# COMPUTE_CLUSTER_ARM_COREPACK_0_COMPUTE_CLUSTER_ARM_COREPACK_0_APBADDR_CTI_CPU1_000730120000h register map
Vendor: Texas Instruments
Peripheral module from a debugger description file (folder am62L).
Registers are 32-bit, read-write, reset 0x0 unless marked. A register's access mark holds for its fields unless they carry their own. Offsets are as the file gives them; lines under a group give offsets from that group; [hi:lo] are bit positions; {n}, {i} and the like mark numbered series; 'fields as' and 'values as' point back to an identical list; <NAME> marks a mode.

## COMPUTE_CLUSTER_ARM_COREPACK_0_APBADDR_CTI_CPU1
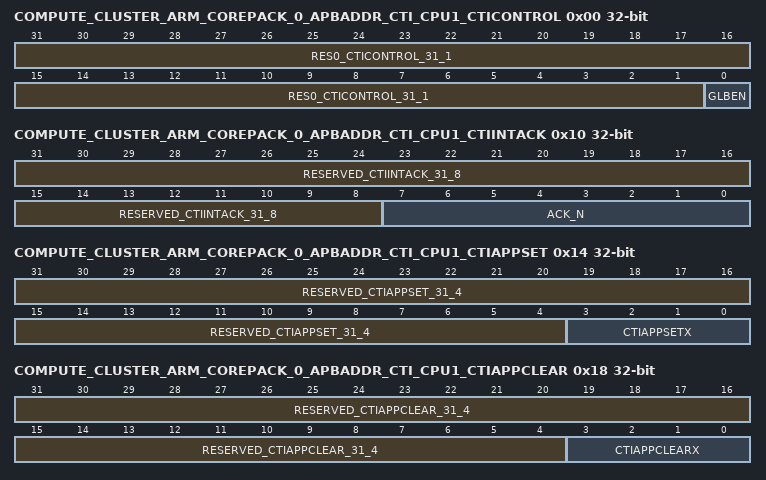
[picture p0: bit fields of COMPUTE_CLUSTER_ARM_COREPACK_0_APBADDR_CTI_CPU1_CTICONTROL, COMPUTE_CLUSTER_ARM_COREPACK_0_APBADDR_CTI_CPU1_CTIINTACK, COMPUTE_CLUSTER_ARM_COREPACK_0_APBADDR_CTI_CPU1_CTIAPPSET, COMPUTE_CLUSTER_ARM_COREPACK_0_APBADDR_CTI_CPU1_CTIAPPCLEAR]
0x00 COMPUTE_CLUSTER_ARM_COREPACK_0_APBADDR_CTI_CPU1_CTICONTROL — CTI Control Register
  [31:1] RES0_CTICONTROL_31_1 — Reserved, RES0.
  [0] GLBEN — Enables or disables the CTI mapping functions. Possible values of this field are: 0 CTI mapping functions disabled. 1 CTI mapping functions enabled. When the mapping functions are disabled, no new events are signaled on either output triggers or output channels. If a previously asserted output trigger has not been acknowledged, it remains asserted after the mapping functions are disabled. All output triggers are disabled by CTI reset.
0x10 COMPUTE_CLUSTER_ARM_COREPACK_0_APBADDR_CTI_CPU1_CTIINTACK — CTI Output Trigger Acknowledge Register
  [31:8] RESERVED_CTIINTACK_31_8 — Reserved RES0
  [7:0] ACK_N — Can be used to create soft acknowledges for output triggers
0x14 COMPUTE_CLUSTER_ARM_COREPACK_0_APBADDR_CTI_CPU1_CTIAPPSET — CTI Application Trigger Set Register
  [31:4] RESERVED_CTIAPPSET_31_4 — Reserved RES0
  [3:0] CTIAPPSETX — Application trigger <x> enable
0x18 COMPUTE_CLUSTER_ARM_COREPACK_0_APBADDR_CTI_CPU1_CTIAPPCLEAR — CTI Application Trigger Clear Register
  [31:4] RESERVED_CTIAPPCLEAR_31_4 — Reserved RES0
  [3:0] CTIAPPCLEARX — Application trigger <x> disable
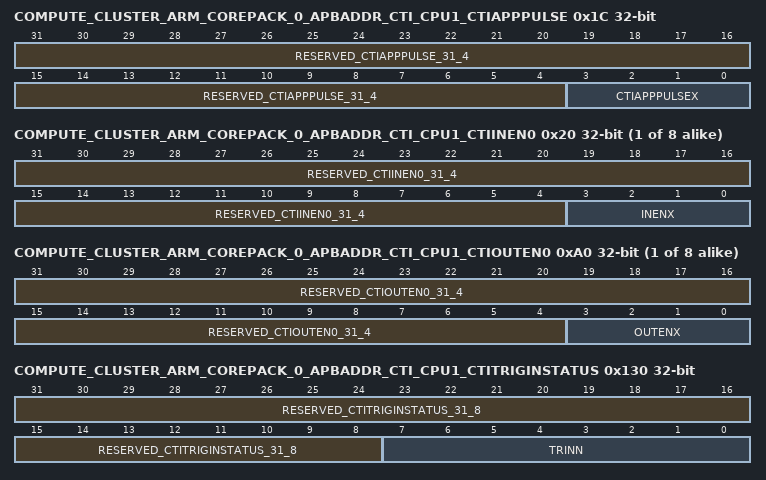
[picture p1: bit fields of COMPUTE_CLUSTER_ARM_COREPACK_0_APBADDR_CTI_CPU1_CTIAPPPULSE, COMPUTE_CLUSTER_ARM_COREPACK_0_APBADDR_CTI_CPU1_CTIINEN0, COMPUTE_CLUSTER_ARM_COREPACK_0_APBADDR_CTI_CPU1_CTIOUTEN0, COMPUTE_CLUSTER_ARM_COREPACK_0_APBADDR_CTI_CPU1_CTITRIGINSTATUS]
0x1C COMPUTE_CLUSTER_ARM_COREPACK_0_APBADDR_CTI_CPU1_CTIAPPPULSE — CTI Application Pulse Register
  [31:4] RESERVED_CTIAPPPULSE_31_4 — Reserved RES0
  [3:0] CTIAPPPULSEX — Generate event pulse on ECT channel <x>.
{0x20+4i} COMPUTE_CLUSTER_ARM_COREPACK_0_APBADDR_CTI_CPU1_CTIINEN{i} (i=0..7) — CTI Input Trigger to Output Channel Enable Register {i}
  [31:4] RESERVED_CTIINEN{i}_31_4 — Reserved RES0
  [3:0] INENX — Input trigger {i} to output channel <x> enable
{0xA0+4i} COMPUTE_CLUSTER_ARM_COREPACK_0_APBADDR_CTI_CPU1_CTIOUTEN{i} (i=0..7) — CTI Input Channel to Output Trigger Enable Register {i}
  [31:4] RESERVED_CTIOUTEN{i}_31_4 — Reserved RES0
  [3:0] OUTENX — Input channel <x> to output trigger {i} enable
0x130 COMPUTE_CLUSTER_ARM_COREPACK_0_APBADDR_CTI_CPU1_CTITRIGINSTATUS — CTI Trigger In Status Register
  [31:8] RESERVED_CTITRIGINSTATUS_31_8 — Reserved RES0
  [7:0] TRINN — Provides the status of the trigger inputs
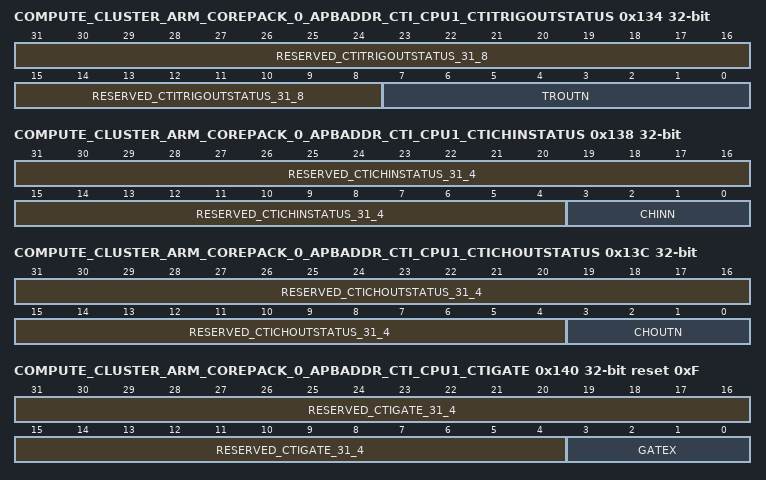
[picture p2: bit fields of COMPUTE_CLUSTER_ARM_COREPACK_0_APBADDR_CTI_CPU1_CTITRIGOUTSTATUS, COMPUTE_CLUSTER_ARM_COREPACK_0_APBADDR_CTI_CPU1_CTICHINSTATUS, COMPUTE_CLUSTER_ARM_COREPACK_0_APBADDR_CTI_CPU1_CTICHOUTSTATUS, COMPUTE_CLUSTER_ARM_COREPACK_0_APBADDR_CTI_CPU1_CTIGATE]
0x134 COMPUTE_CLUSTER_ARM_COREPACK_0_APBADDR_CTI_CPU1_CTITRIGOUTSTATUS — CTI Trigger Out Status Register
  [31:8] RESERVED_CTITRIGOUTSTATUS_31_8 — Reserved RES0
  [7:0] TROUTN — Provides the status of the trigger outputs
0x138 COMPUTE_CLUSTER_ARM_COREPACK_0_APBADDR_CTI_CPU1_CTICHINSTATUS — CTI Channel In Status Register
  [31:4] RESERVED_CTICHINSTATUS_31_4 — Reserved RES0
  [3:0] CHINN — Provides the raw status of the ECT channel inputs to the CTI
0x13C COMPUTE_CLUSTER_ARM_COREPACK_0_APBADDR_CTI_CPU1_CTICHOUTSTATUS — CTI Channel Out Status Register
  [31:4] RESERVED_CTICHOUTSTATUS_31_4 — Reserved RES0
  [3:0] CHOUTN — Provides the status of the ECT channel outputs from the CTI
0x140 COMPUTE_CLUSTER_ARM_COREPACK_0_APBADDR_CTI_CPU1_CTIGATE reset 0xF — CTI Channel Gate Enable Register
  [31:4] RESERVED_CTIGATE_31_4 — Reserved RES0
  [3:0] GATEX — Determines whether events on channels propagate through the CTM to other ECT components or from the CTM into the CTI
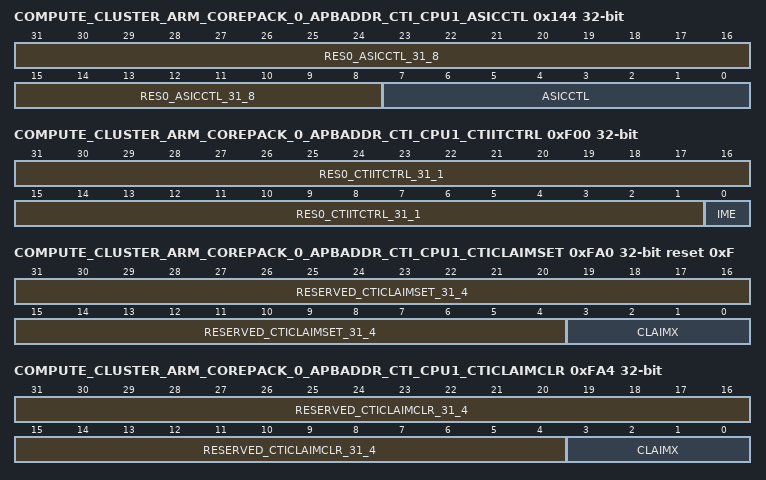
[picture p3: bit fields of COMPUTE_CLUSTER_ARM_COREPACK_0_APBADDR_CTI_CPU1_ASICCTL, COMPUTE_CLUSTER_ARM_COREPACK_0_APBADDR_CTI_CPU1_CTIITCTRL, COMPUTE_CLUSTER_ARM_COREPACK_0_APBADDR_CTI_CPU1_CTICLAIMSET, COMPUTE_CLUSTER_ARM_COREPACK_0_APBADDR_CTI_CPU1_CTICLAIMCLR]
0x144 COMPUTE_CLUSTER_ARM_COREPACK_0_APBADDR_CTI_CPU1_ASICCTL — CTI External Multiplexor Control register
  [31:8] RES0_ASICCTL_31_8 — Reserved, RES0.
  [7:0] ASICCTL — IMPLEMENTATION DEFINED ASIC control. Provides a control for external multiplexing of additional triggers into the CTI.If external multiplexing of trigger signals is implemented then the number of multiplexed signals on each trigger must be reflected in CTIDEVID.EXTMUXNUM.If CTIDEVID.EXTMUXNUM is zero, this field is RAZ.
0xF00 COMPUTE_CLUSTER_ARM_COREPACK_0_APBADDR_CTI_CPU1_CTIITCTRL — CTI Integration mode Control Register
  [31:1] RES0_CTIITCTRL_31_1 — Reserved, RES0.
  [0] IME — Integration mode enable. When IME == 1, the device reverts to an integration mode to enable integration testing or topology detection. The integration mode behavior is IMPLEMENTATION DEFINED. 0 Normal operation. 1 Integration mode enabled.
0xFA0 COMPUTE_CLUSTER_ARM_COREPACK_0_APBADDR_CTI_CPU1_CTICLAIMSET reset 0xF — CTI Claim Set
  [31:4] RESERVED_CTICLAIMSET_31_4 — Reserved RES0
  [3:0] CLAIMX — CLAIM tag set bit
0xFA4 COMPUTE_CLUSTER_ARM_COREPACK_0_APBADDR_CTI_CPU1_CTICLAIMCLR — CTI Claim Clear
  [31:4] RESERVED_CTICLAIMCLR_31_4 — Reserved RES0
  [3:0] CLAIMX — Clear CLAIM tag
0xFA8 COMPUTE_CLUSTER_ARM_COREPACK_0_APBADDR_CTI_CPU1_CTIDEVAFF0 reset 0x80000001 — CTI Device Affinity Register 0
  [31:0] CTIDEVAFF0 — MPIDR_EL1 low half. Read-only copy of the low half of MPIDR_EL1, as seen from the highest implemented exception level.
0xFAC COMPUTE_CLUSTER_ARM_COREPACK_0_APBADDR_CTI_CPU1_CTIDEVAFF1 — CTI Device Affinity Register 1
  [31:0] CTIDEVAFF1 — MPIDR_EL1 high half. Read-only copy of the high half of MPIDR_EL1, as seen from the highest implemented exception level.
0xFB0 COMPUTE_CLUSTER_ARM_COREPACK_0_APBADDR_CTI_CPU1_CTILAR — CTI Lock Access Register
  [31:0] KEY — Lock Access control. Writing the key value 0xC5ACCE55 to this field unlocks the lock, enabling write accesses to this component's registers through a memory-mapped interface.Writing any other value to this register locks the lock, disabling write accesses to this component's registers through a memory mapped interface.
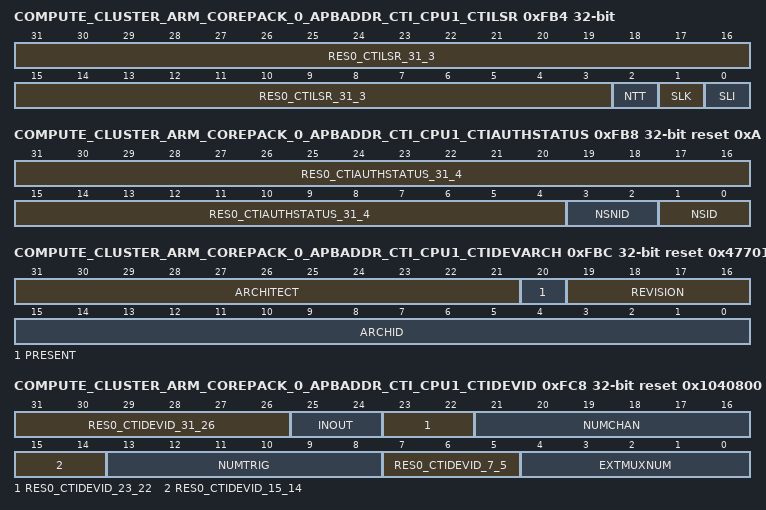
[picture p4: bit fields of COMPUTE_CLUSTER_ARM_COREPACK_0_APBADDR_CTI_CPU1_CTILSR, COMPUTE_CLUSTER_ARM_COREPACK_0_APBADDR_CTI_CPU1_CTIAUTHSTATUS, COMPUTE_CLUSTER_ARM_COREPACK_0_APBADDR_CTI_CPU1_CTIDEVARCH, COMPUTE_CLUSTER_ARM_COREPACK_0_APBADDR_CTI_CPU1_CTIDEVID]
0xFB4 COMPUTE_CLUSTER_ARM_COREPACK_0_APBADDR_CTI_CPU1_CTILSR — CTI Lock Status Register
  [31:3] RES0_CTILSR_31_3 — Reserved, RES0.
  [2] NTT — Not thirty-two bit access required. RAZ.
  [1] SLK — Software lock status for this component. For an access to LSR that is not a memory-mapped access, or when the software lock is not implemented, this field is RES0.For memory-mapped accesses when the software lock is implemented, possible values of this field are: 0 Lock clear. Writes are permitted to this component's registers. 1 Lock set. Writes to this component's registers are ignored, and reads have no side effects.
  [0] SLI — Software lock implemented. For an access to LSR that is not a memory-mapped access, this field is RAZ. For memory-mapped accesses, the value of this field is IMPLEMENTATION DEFINED. Permitted values are: 0 Software lock not implemented or not memory-mapped access. 1 Software lock implemented and memory-mapped access.
0xFB8 COMPUTE_CLUSTER_ARM_COREPACK_0_APBADDR_CTI_CPU1_CTIAUTHSTATUS reset 0xA — CTI Authentication Status Register
  [31:4] RES0_CTIAUTHSTATUS_31_4 — Reserved, RES0.
  [3:2] NSNID — If EL3 is not implemented and the processor is Secure, holds the same value as DBGAUTHSTATUS_EL1.SNID.Otherwise, holds the same value as DBGAUTHSTATUS_EL1.NSNID.
  [1:0] NSID — If EL3 is not implemented and the processor is Secure, holds the same value as DBGAUTHSTATUS_EL1.SID.Otherwise, holds the same value as DBGAUTHSTATUS_EL1.NSID.
0xFBC COMPUTE_CLUSTER_ARM_COREPACK_0_APBADDR_CTI_CPU1_CTIDEVARCH reset 0x47701A14 — CTI Device Architecture Register
  [31:21] ARCHITECT — Defines the architecture of the component. For CTI, this is ARM Limited.Bits [31:28] are the JEP 106 continuation code, 0x4.Bits [27:21] are the JEP 106 ID code, 0x3B.
  [20] PRESENT — When set to 1, indicates that the DEVARCH is present.This field is 1 in v8-A.
  [19:16] REVISION — Defines the architecture revision. For architectures defined by ARM this is the minor revision.For CTI, the revision defined by v8-A is 0x0.All other values are reserved.
  [15:0] ARCHID — Defines this part to be a v8-A debug component. For architectures defined by ARM this is further subdivided.For CTI:Bits [15:12] are the architecture version, 0x1.Bits [11:0] are the architecture part number, 0xA14.This corresponds to CTI architecture version CTIv2.
0xFC0 COMPUTE_CLUSTER_ARM_COREPACK_0_APBADDR_CTI_CPU1_CTIDEVID2 — CTI Device ID Register 2
  [31:0] RES0_CTIDEVID2_31_0 — Reserved, RES0.
0xFC4 COMPUTE_CLUSTER_ARM_COREPACK_0_APBADDR_CTI_CPU1_CTIDEVID1 — CTI Device ID Register 1
  [31:0] RES0_CTIDEVID1_31_0 — Reserved, RES0.
0xFC8 COMPUTE_CLUSTER_ARM_COREPACK_0_APBADDR_CTI_CPU1_CTIDEVID reset 0x1040800 — CTI Device ID Register 0
  [31:26] RES0_CTIDEVID_31_26 — Reserved, RES0.
  [25:24] INOUT — Input/output options. Indicates presence of the input gate. If the CTM is not implemented, this field is RAZ. 00 CTIGATE does not mask propagation of input events from external channels. 01 CTIGATE masks propagation of input events from external channels. All other values are reserved.
  [23:22] RES0_CTIDEVID_23_22 — Reserved, RES0.
  [21:16] NUMCHAN — Number of ECT channels implemented. IMPLEMENTATION DEFINED. For v8-A, valid values are: 000011 3 channels [0..2] implemented. 000100 4 channels [0..3] implemented. 000101 5 channels [0..4] implemented. 000110 6 channels [0..5] implemented. and so on up to 0b100000, 32 channels [0..31] implemented.All other values are reserved.
  [15:14] RES0_CTIDEVID_15_14 — Reserved, RES0.
  [13:8] NUMTRIG — Number of triggers implemented. IMPLEMENTATION DEFINED. This is one more than the index of the largest trigger, rather than the actual number of triggers.For v8-A, valid values are: 000011 Up to 3 triggers [0..2] implemented. 001000 Up to 8 triggers [0..7] implemented. 001001 Up to 9 triggers [0..8] implemented. 001010 Up to 10 triggers [0..9] implemented. and so on up to 0b100000, 32 triggers [0..31] implemented.All other values are reserved. If the Trace Extension is implemented, this field must be at least 001000. There is no guarantee that any of the implemented triggers, including the highest numbered, are connected to any components.
  [7:5] RES0_CTIDEVID_7_5 — Reserved, RES0.
  [4:0] EXTMUXNUM — Maximum number of external triggers available for multiplexing into the CTI. This relates only to additional external triggers outside those defined for v8-A.
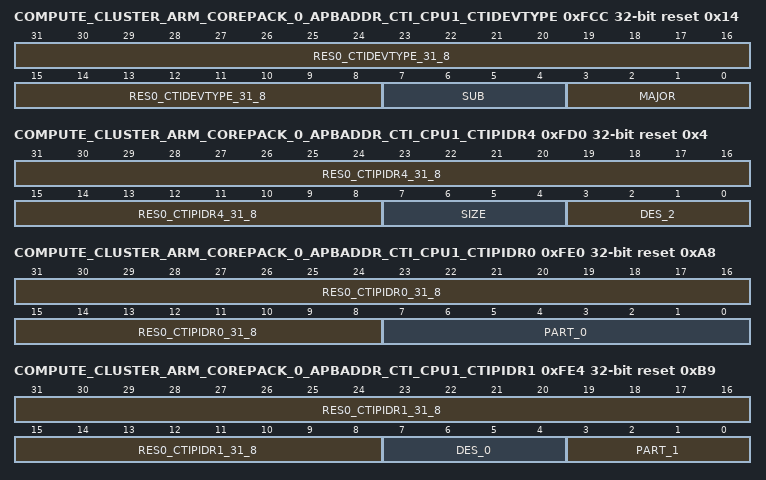
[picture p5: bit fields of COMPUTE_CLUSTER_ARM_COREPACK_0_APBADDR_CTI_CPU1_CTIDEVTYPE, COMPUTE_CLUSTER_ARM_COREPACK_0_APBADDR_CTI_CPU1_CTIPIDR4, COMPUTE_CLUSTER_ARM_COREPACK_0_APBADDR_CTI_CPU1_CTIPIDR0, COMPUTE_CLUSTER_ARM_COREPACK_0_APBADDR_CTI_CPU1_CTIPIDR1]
0xFCC COMPUTE_CLUSTER_ARM_COREPACK_0_APBADDR_CTI_CPU1_CTIDEVTYPE reset 0x14 — CTI Device Type Register
  [31:8] RES0_CTIDEVTYPE_31_8 — Reserved, RES0.
  [7:4] SUB — Subtype. Must read as 0x1 to indicate this is a processor component.
  [3:0] MAJOR — Major type. Must read as 0x4 to indicate this is a cross-trigger component.
0xFD0 COMPUTE_CLUSTER_ARM_COREPACK_0_APBADDR_CTI_CPU1_CTIPIDR4 reset 0x4 — CTI Peripheral Identification Register 4
  [31:8] RES0_CTIPIDR4_31_8 — Reserved, RES0.
  [7:4] SIZE — Size of the component. RAZ. Log2 of the number of 4KB pages from the start of the component to the end of the component ID registers.
  [3:0] DES_2 — Designer, JEP106 continuation code, least significant nibble. For ARM Limited, this field is 0b0100.
{0xFC0+4i} COMPUTE_CLUSTER_ARM_COREPACK_0_APBADDR_CTI_CPU1_CTIPIDR{i} (i=5..7) — CTI Peripheral Identification Register {i}
  [31:0] RESERVED_CTIPIDR{i}_31_0 — Reserved RES0
0xFE0 COMPUTE_CLUSTER_ARM_COREPACK_0_APBADDR_CTI_CPU1_CTIPIDR0 reset 0xA8 — CTI Peripheral Identification Register 0
  [31:8] RES0_CTIPIDR0_31_8 — Reserved, RES0.
  [7:0] PART_0 — Part number, least significant byte.
0xFE4 COMPUTE_CLUSTER_ARM_COREPACK_0_APBADDR_CTI_CPU1_CTIPIDR1 reset 0xB9 — CTI Peripheral Identification Register 1
  [31:8] RES0_CTIPIDR1_31_8 — Reserved, RES0.
  [7:4] DES_0 — Designer, least significant nibble of JEP106 ID code. For ARM Limited, this field is 0b1011.
  [3:0] PART_1 — Part number, most significant nibble.
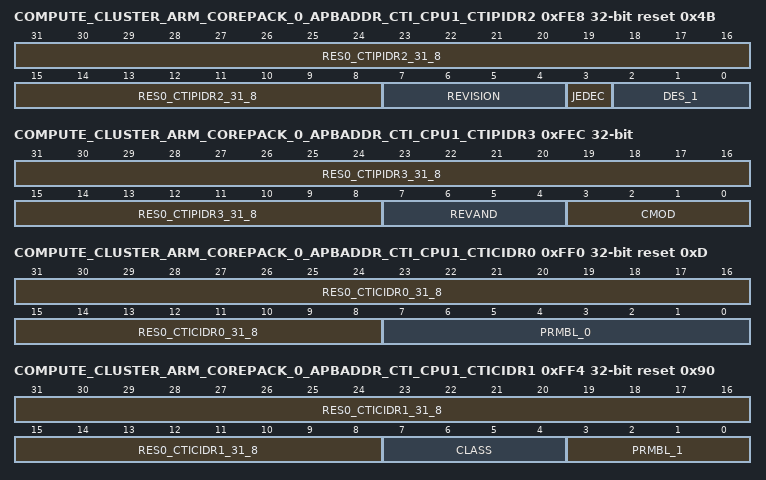
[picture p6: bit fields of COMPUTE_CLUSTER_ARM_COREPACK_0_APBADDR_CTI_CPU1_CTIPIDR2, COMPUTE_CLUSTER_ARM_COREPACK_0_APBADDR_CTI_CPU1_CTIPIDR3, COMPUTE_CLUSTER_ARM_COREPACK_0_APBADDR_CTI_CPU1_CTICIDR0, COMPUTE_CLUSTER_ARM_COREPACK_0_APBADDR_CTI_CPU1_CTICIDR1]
0xFE8 COMPUTE_CLUSTER_ARM_COREPACK_0_APBADDR_CTI_CPU1_CTIPIDR2 reset 0x4B — CTI Peripheral Identification Register 2
  [31:8] RES0_CTIPIDR2_31_8 — Reserved, RES0.
  [7:4] REVISION — Part major revision. Parts can also use this field to extend Part number to 16-bits.
  [3] JEDEC — RAO. Indicates a JEP106 identity code is used.
  [2:0] DES_1 — Designer, most significant bits of JEP106 ID code. For ARM Limited, this field is 0b011.
0xFEC COMPUTE_CLUSTER_ARM_COREPACK_0_APBADDR_CTI_CPU1_CTIPIDR3 — CTI Peripheral Identification Register 3
  [31:8] RES0_CTIPIDR3_31_8 — Reserved, RES0.
  [7:4] REVAND — Part minor revision. Parts using CTIPIDR2.REVISION as an extension to the Part number must use this field as a major revision number.
  [3:0] CMOD — Customer modified. Indicates someone other than the Designer has modified the component.
0xFF0 COMPUTE_CLUSTER_ARM_COREPACK_0_APBADDR_CTI_CPU1_CTICIDR0 reset 0xD — CTI Component Identification Register 0
  [31:8] RES0_CTICIDR0_31_8 — Reserved, RES0.
  [7:0] PRMBL_0 — Preamble. Must read as 0x0D.
0xFF4 COMPUTE_CLUSTER_ARM_COREPACK_0_APBADDR_CTI_CPU1_CTICIDR1 reset 0x90 — CTI Component Identification Register 1
  [31:8] RES0_CTICIDR1_31_8 — Reserved, RES0.
  [7:4] CLASS — Component class. Reads as 0x9, debug component.
  [3:0] PRMBL_1 — Preamble. RAZ.
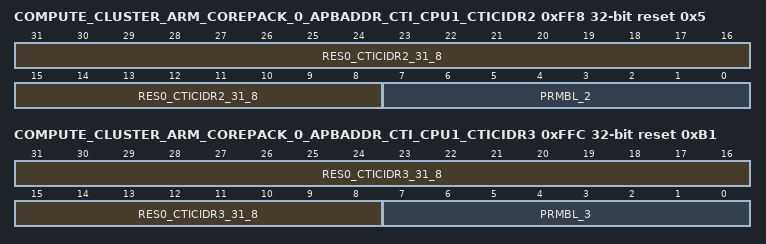
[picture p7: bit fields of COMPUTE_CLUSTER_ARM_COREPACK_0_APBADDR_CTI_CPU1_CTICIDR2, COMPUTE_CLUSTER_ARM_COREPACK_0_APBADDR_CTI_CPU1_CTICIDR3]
0xFF8 COMPUTE_CLUSTER_ARM_COREPACK_0_APBADDR_CTI_CPU1_CTICIDR2 reset 0x5 — CTI Component Identification Register 2
  [31:8] RES0_CTICIDR2_31_8 — Reserved, RES0.
  [7:0] PRMBL_2 — Preamble. Must read as 0x05.
0xFFC COMPUTE_CLUSTER_ARM_COREPACK_0_APBADDR_CTI_CPU1_CTICIDR3 reset 0xB1 — CTI Component Identification Register 3
  [31:8] RES0_CTICIDR3_31_8 — Reserved, RES0.
  [7:0] PRMBL_3 — Preamble. Must read as 0xB1.
